AUTOSAR XML (schema 00046)
package /Runnables_lab2
  sender receiver interface inputs
    data val1: type=uint32
    data val2: type=uint32
  sender receiver interface output
    data sum: type=uint32
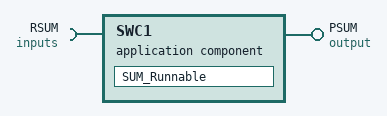
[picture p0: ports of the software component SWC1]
  application sw component type SWC1
    require port RSUM: required-interface=inputs
    provide port PSUM: provided-interface=output
    behavior sum_Behavior
      runnable SUM_Runnable: symbol=SUM
        data-read-access:
          access VAL1_DATA: accessed-variable=RSUM.val1
          access VAL2_DATA: accessed-variable=RSUM.val2
        data-write-access:
          access SUM_DATA: accessed-variable=PSUM.sum
